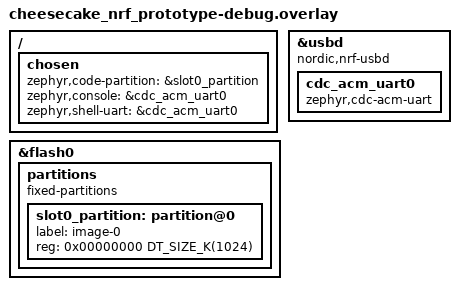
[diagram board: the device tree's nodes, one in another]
/ {
	chosen {
		zephyr,code-partition = &slot0_partition;
		zephyr,console = &cdc_acm_uart0;
		zephyr,shell-uart = &cdc_acm_uart0;
	};
};

&flash0 {
	/delete-node/ partitions;
	partitions {
		compatible = "fixed-partitions";
		#address-cells = <1>;
		#size-cells = <1>;

		slot0_partition: partition@0 {
			label = "image-0";
			reg = <0x00000000 DT_SIZE_K(1024)>;
		};
	};
};

zephyr_udc0: &usbd {
	compatible = "nordic,nrf-usbd";
	status = "okay";
	cdc_acm_uart0: cdc_acm_uart0 {
		compatible = "zephyr,cdc-acm-uart";
	};
};
